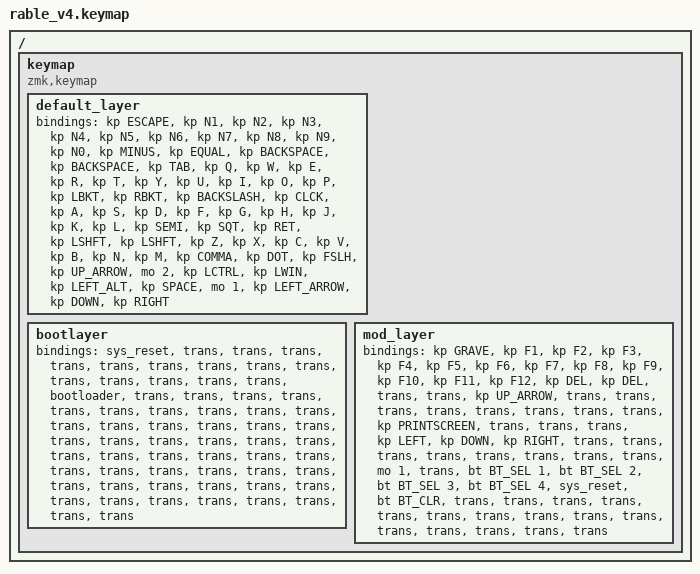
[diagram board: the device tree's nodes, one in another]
/*
 * Copyright (c) 2021 Nick Winans
 *
 * SPDX-License-Identifier: MIT
 */

#include <behaviors.dtsi>
#include <dt-bindings/zmk/bt.h>
#include <dt-bindings/zmk/keys.h>

/ {
    keymap {
        compatible = "zmk,keymap";

        default_layer {
            bindings = <
&kp ESCAPE  &kp N1  &kp N2  &kp N3  &kp N4  &kp N5  &kp N6  &kp N7  &kp N8  &kp N9  &kp N0  &kp MINUS  &kp EQUAL  &kp BACKSPACE  &kp BACKSPACE  &kp TAB  &kp Q  &kp W  &kp E  &kp R  &kp T  &kp Y  &kp U  &kp I  &kp O  &kp P  &kp LBKT  &kp RBKT  &kp BACKSLASH  &kp CLCK  &kp A  &kp S  &kp D  &kp F  &kp G  &kp H  &kp J  &kp K  &kp L  &kp SEMI  &kp SQT  &kp RET  &kp LSHFT  &kp LSHFT  &kp Z  &kp X  &kp C  &kp V  &kp B  &kp N  &kp M  &kp COMMA  &kp DOT  &kp FSLH  &kp UP_ARROW  &mo 2  &kp LCTRL  &kp LWIN  &kp LEFT_ALT  &kp SPACE  &mo 1  &kp LEFT_ARROW  &kp DOWN  &kp RIGHT
            >;
        };

        bootlayer {
            // ----------------------------------------------------------------------------------------------------------------
            // |        |    |     |     |     |     |     |     |     |     |     |     |     |     |     |   `~    |
            // |        |    |     |     |     |     |     |     |     |     |     |     |     |     |     |         |
            // |        |    |     |     |     |     |     |LEFT |DOWN |  UP |RIGHT|     |     |     |     |         |
            // |        |    |     |     |     |     |     |     |     |     |     |     |     |     |     |         |
            // |        |    |     |     |                                               |     |     |     |         |
            // ----------------------------------------------------------------------------------------------------------------

            bindings = <
&sys_reset  &trans  &trans  &trans  &trans  &trans  &trans  &trans  &trans  &trans  &trans  &trans  &trans  &trans  &trans  &bootloader  &trans  &trans  &trans  &trans  &trans  &trans  &trans  &trans  &trans  &trans  &trans  &trans  &trans  &trans  &trans  &trans  &trans  &trans  &trans  &trans  &trans  &trans  &trans  &trans  &trans  &trans  &trans  &trans  &trans  &trans  &trans  &trans  &trans  &trans  &trans  &trans  &trans  &trans  &trans  &trans  &trans  &trans  &trans  &trans  &trans  &trans  &trans  &trans
            >;
        };

        mod_layer {
            // ----------------------------------------------------------------------------------------------------------------
            // |        |    | BT 1|BT 2 |BT 3 |BT 4 |     |     |     |     |     |     |     |     |BT CLR |         |
            // |        |    | RST | BOOT|     |     |     |     |     |     |     |     |     |     |       |         |
            // |        |    | USB | BLE |     |     |     |     |     |     |     |     |     |     |RGB TOG|         |
            // |        |    |EP_ON|EP_OFF|EP_TOG|     |     |     |     |     |     |     |     |     |       |         |
            // |        |    |     |     |                                               |     |     |       |         |
            // ----------------------------------------------------------------------------------------------------------------

            bindings = <
&kp GRAVE  &kp F1  &kp F2  &kp F3  &kp F4  &kp F5  &kp F6  &kp F7  &kp F8  &kp F9  &kp F10  &kp F11  &kp F12  &kp DEL  &kp DEL  &trans  &trans  &kp UP_ARROW  &trans  &trans  &trans  &trans  &trans  &trans  &trans  &trans  &kp PRINTSCREEN  &trans  &trans  &trans  &kp LEFT  &kp DOWN  &kp RIGHT  &trans  &trans  &trans  &trans  &trans  &trans  &trans  &trans  &mo 1  &trans  &bt BT_SEL 1  &bt BT_SEL 2  &bt BT_SEL 3  &bt BT_SEL 4  &sys_reset  &bt BT_CLR  &trans  &trans  &trans  &trans  &trans  &trans  &trans  &trans  &trans  &trans  &trans  &trans  &trans  &trans  &trans
            >;
        };
    };
};
